AUTOSAR XML (schema 00050)
package /ComponentTypes
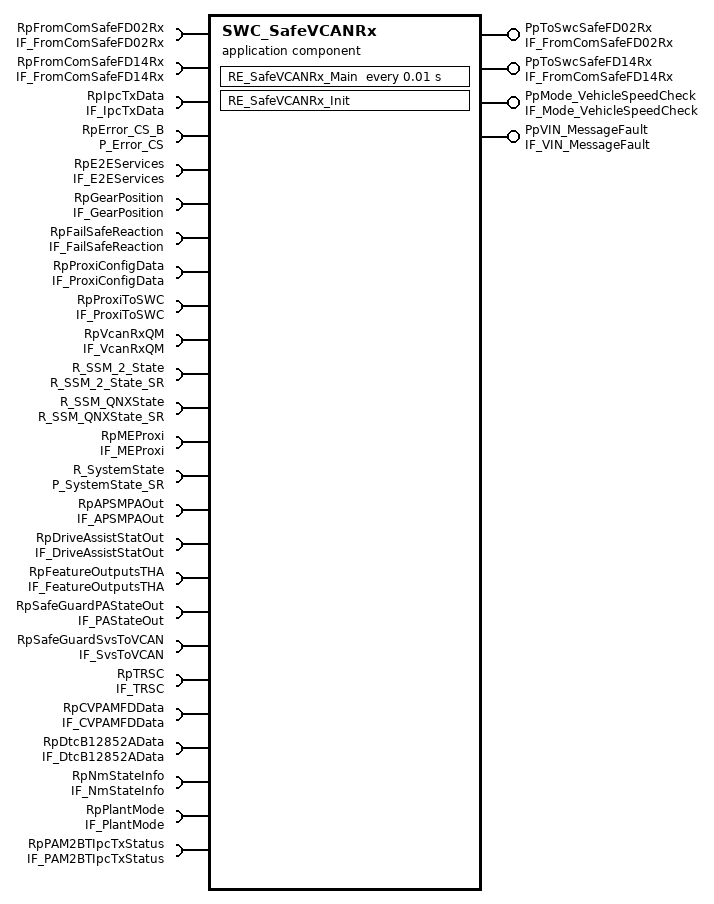
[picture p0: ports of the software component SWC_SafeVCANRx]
  application sw component type SWC_SafeVCANRx
    require port RpFromComSafeFD02Rx: required-interface=IF_FromComSafeFD02Rx
      required-com-specs:
        data-element=PdlPosActual, init-value=1
        data-element=Active_Park_Mode, enable-update=true, init-value=0
        data-element=Active_Park_Prox_Chime, enable-update=true, init-value=0
        data-element=APARequestSts, enable-update=true, init-value=0
        data-element=Backup_Cam_Delay, enable-update=true, init-value=0
        data-element=Brk_Stat, init-value=0
        data-element=CmdIgnSts, enable-update=true, init-value=0
        data-element=DriverDoorSts, enable-update=true, init-value=0
        data-element=DynamicGrid, init-value=1
        data-element=ExternalTemperature, init-value=0
        data-element=FT_PAMRequestSts, enable-update=true, init-value=0
        data-element=Fwrd_Cam_Guidelines, enable-update=true, init-value=0
        data-element=GearEngaged, enable-update=true, init-value=0
        data-element=HAS_Status_C2, init-value=0
        data-element=LanguageSelection, enable-update=true, init-value=0
        data-element=LatAcceleration_BSM, init-value=4095
        data-element=LHRDoorSts, enable-update=true, init-value=0
        data-element=LongAcceleration_BSM, init-value=4095
        data-element=LwsAngle, init-value=0
        data-element=LwsAngleType, init-value=0
        data-element=LwsSpeed, init-value=0
        data-element=MRM_STATUS_C2, init-value=0
        data-element=PamChimeVolumeFront, enable-update=true, init-value=1
        data-element=PamChimeVolumeRear, enable-update=true, init-value=1
        data-element=PAMRequestSts, enable-update=true, init-value=0
        data-element=PsngrDoorSts, enable-update=true, init-value=0
        data-element=Rear_Brk_Asst, enable-update=true, init-value=0
        data-element=RHatchSts, enable-update=true, init-value=0
        data-element=RHRDoorSts, enable-update=true, init-value=0
        data-element=ShiftLeverPosition, enable-update=true, init-value=0
        data-element=SVC_Guidelines, enable-update=true, init-value=0
        data-element=TargetGear, init-value=15
        data-element=TCASERANGESTATUS, enable-update=true, init-value=0
        data-element=TGW_CAMERA_DISP_STAT, enable-update=true, init-value=0
        data-element=TrailerConnectionSts, init-value=0
        data-element=TRANS_ADAS_Inhibit, init-value=0
        data-element=TransmissionSailingSts, init-value=0
        data-element=VehicleSpeedVSOSig, init-value=0
        data-element=YawRate_BSM, init-value=4095
        data-element=VIN_MSG, filter=data-filter-type=ALWAYS, init-value=0
        {data-element=VIN_DATA, filter=data-filter-type=ALWAYS, init-value=[rule-based-values={rule=FILL_UNTIL_END, rule-arguments=0}]}
        data-element=RR_Lvl_Adj, filter=data-filter-type=ALWAYS, init-value=0
        data-element=RR_Lvl, filter=data-filter-type=ALWAYS, init-value=254
        data-element=RL_Lvl_Adj, filter=data-filter-type=ALWAYS, init-value=0
        data-element=RL_Lvl, filter=data-filter-type=ALWAYS, init-value=254
        data-element=HU_TRSC_EnableBtn_Sts, enable-update=true, filter=data-filter-type=ALWAYS, init-value=0
        data-element=GearEngagedForDisplay, filter=data-filter-type=ALWAYS, init-value=31
        data-element=FR_Lvl_Adj, filter=data-filter-type=ALWAYS, init-value=0
        data-element=FR_Lvl, filter=data-filter-type=ALWAYS, init-value=254
        data-element=FL_Lvl_Adj, filter=data-filter-type=ALWAYS, init-value=0
        data-element=FL_Lvl, filter=data-filter-type=ALWAYS, init-value=254
        data-element=ESS_ENG_ST_W, filter=data-filter-type=ALWAYS, init-value=15
        data-element=EngineSts_W, filter=data-filter-type=ALWAYS, init-value=0
        data-element=ECM_TRSC_Resp, enable-update=true, filter=data-filter-type=ALWAYS, init-value=0
        data-element=ECM_THA_Resp, enable-update=true, filter=data-filter-type=ALWAYS, init-value=0
        data-element=ASCM_SysFail, enable-update=true, filter=data-filter-type=ALWAYS, init-value=0
        data-element=ASCM_Stat, enable-update=true, filter=data-filter-type=ALWAYS, init-value=0
        data-element=THA_SteeringTouchStat, filter=data-filter-type=ALWAYS, init-value=0
        data-element=EPS_THA_SteeringTorqueResp, filter=data-filter-type=ALWAYS, init-value=0
        data-element=EPS_THA_DriverTorqueOverride, filter=data-filter-type=ALWAYS, init-value=0
        data-element=EPS_SteeringTouq_Resp, filter=data-filter-type=ALWAYS, init-value=0
        data-element=EPS_SteeringTouchStat, filter=data-filter-type=ALWAYS, init-value=0
        data-element=ShiftLeverPositionReq, enable-update=true, filter=data-filter-type=ALWAYS, init-value=0
        data-element=Shifter_ADAS_Inhibit, filter=data-filter-type=ALWAYS, init-value=0
        data-element=ITBM_TrlrStat, enable-update=true, filter=data-filter-type=ALWAYS, init-value=0
        data-element=CM_TCH_Y_COORD, enable-update=true, filter=data-filter-type=ALWAYS, init-value=0
        data-element=CM_TCH_X_COORD, enable-update=true, filter=data-filter-type=ALWAYS, init-value=0
        data-element=CM_TCH_STAT, enable-update=true, filter=data-filter-type=ALWAYS, init-value=0
        data-element=CameraDisplaySts2, enable-update=true, filter=data-filter-type=ALWAYS, init-value=0
    require port RpFromComSafeFD14Rx: required-interface=IF_FromComSafeFD14Rx
      required-com-specs:
        data-element=FD14_PdlPosActual, init-value=1
        data-element=FD14_ACC_Systemsts, init-value=0
        data-element=FD14_Brk_Stat, init-value=0
        data-element=FD14_BrkPdl_Stat, init-value=3
        data-element=FD14_BrkTrq, init-value=32767
        data-element=FD14_BrkTrq_Driver, init-value=32767
        data-element=FD14_BSM_THA_Brk_Resp, enable-update=true, init-value=0
        data-element=FD14_EPBSts, enable-update=true, init-value=0
        data-element=FD14_EPS_HandsOnRecognition, init-value=0
        data-element=FD14_ESC_TRSC_Brk_Resp, enable-update=true, init-value=0
        data-element=FD14_ExternalBrkRequestsDisabled, init-value=0
        data-element=FD14_HAS_Status, init-value=0
        data-element=FD14_LatAcceleration_BSM, init-value=4095
        data-element=FD14_LatAccelerationFailSts_BSM, init-value=0
        data-element=FD14_LatAccelerationOffset_BSM, init-value=255
        data-element=FD14_LHF_FastPulseCounter, init-value=0
        data-element=FD14_LHF_Spin, init-value=0
        data-element=FD14_LHF_WheelSensorFailSts, init-value=0
        data-element=FD14_LHFWheelSpeed, init-value=0
        data-element=FD14_LHR_FastPulseCounter, init-value=0
        data-element=FD14_LHR_Spin, init-value=0
        data-element=FD14_LHR_WheelSensorFailSts, init-value=0
        data-element=FD14_LHRWheelSpeed, init-value=0
        data-element=FD14_LongAcceleration_BSM, init-value=4095
        data-element=FD14_LongAccelerationFailSts_BSM, init-value=0
        data-element=FD14_LongAccelerationOffset_BSM, init-value=255
        data-element=FD14_LwsAngle, init-value=0
        data-element=FD14_LwsAngleType, init-value=0
        data-element=FD14_LwsSpeed, init-value=0
        data-element=FD14_PAM_Brk_Rq_RspSts, init-value=0
        data-element=FD14_ParkingGearShiftReq_BSM, init-value=0
        data-element=FD14_ParkingInterventionSts, init-value=0
        data-element=FD14_REF_VEH_SPEED, init-value=1023
        data-element=FD14_RHF_FastPulseCounter, init-value=0
        data-element=FD14_RHF_Spin, init-value=0
        data-element=FD14_RHF_WheelSensorFailSts, init-value=0
        data-element=FD14_RHFWheelSpeed, init-value=0
        data-element=FD14_RHR_FastPulseCounter, init-value=0
        data-element=FD14_RHR_Spin, init-value=0
        data-element=FD14_RHR_WheelSensorFailSts, init-value=0
        data-element=FD14_RHRWheelSpeed, init-value=0
        data-element=FD14_Slope, init-value=0
        data-element=FD14_SPM_Lat_Ctrl_ResponseSts, init-value=0
        data-element=FD14_Steering_Column_Torque, init-value=0
        data-element=FD14_VehicleSpeedVSOSig, init-value=0
        data-element=FD14_VehicleSpeedVSOSig_B2, init-value=0
        data-element=FD14_VehicleStandStillSts, init-value=1
        data-element=FD14_YawRate_BSM, init-value=4095
        data-element=FD14_YawRateFailSts_BSM, init-value=0
        data-element=FD14_ESS_ENG_ST_W, enable-update=true, filter=data-filter-type=ALWAYS, init-value=15
        data-element=FD14_EngineSts_W, filter=data-filter-type=ALWAYS, init-value=3
        data-element=FD14_ECM_TRSC_Resp, enable-update=true, filter=data-filter-type=ALWAYS, init-value=0
        data-element=FD14_ECM_THA_Resp, enable-update=true, filter=data-filter-type=ALWAYS, init-value=0
        data-element=FD14_THA_SteeringTouchStat, filter=data-filter-type=ALWAYS, init-value=0
        data-element=FD14_EPS_THA_SteeringTorqueResp, filter=data-filter-type=ALWAYS, init-value=0
        data-element=FD14_EPS_THA_DriverTorqueOverride, filter=data-filter-type=ALWAYS, init-value=0
        data-element=FD14_EPS_SteeringTouq_Resp, filter=data-filter-type=ALWAYS, init-value=0
        data-element=FD14_EPS_SteeringTouchStat, filter=data-filter-type=ALWAYS, init-value=0
    provide port PpToSwcSafeFD02Rx: provided-interface=IF_FromComSafeFD02Rx
      provided-com-specs:
        data-element=CameraDisplaySts2, init-value=0
        data-element=CM_TCH_STAT, init-value=0
        data-element=CM_TCH_X_COORD, init-value=0
        data-element=CM_TCH_Y_COORD, init-value=0
        data-element=EPS_SteeringTouchStat, init-value=0
        data-element=EPS_SteeringTouq_Resp, init-value=0
        data-element=EPS_THA_DriverTorqueOverride, init-value=0
        data-element=EPS_THA_SteeringTorqueResp, init-value=0
        data-element=THA_SteeringTouchStat, init-value=0
        data-element=ITBM_TrlrStat, init-value=0
        data-element=Shifter_ADAS_Inhibit, init-value=0
        data-element=ShiftLeverPositionReq, init-value=0
        data-element=PdlPosActual, init-value=1
        data-element=ASCM_Stat, init-value=0
        data-element=ASCM_SysFail, init-value=0
        data-element=ECM_THA_Resp, init-value=0
        data-element=ECM_TRSC_Resp, init-value=0
        data-element=EngineSts_W, init-value=3
        data-element=ESS_ENG_ST_W, init-value=15
        data-element=FL_Lvl, init-value=254
        data-element=FL_Lvl_Adj, init-value=0
        data-element=FR_Lvl, init-value=254
        data-element=FR_Lvl_Adj, init-value=0
        data-element=GearEngagedForDisplay, init-value=31
        data-element=HU_TRSC_EnableBtn_Sts, init-value=0
        data-element=RL_Lvl, init-value=254
        data-element=RL_Lvl_Adj, init-value=0
        data-element=RR_Lvl, init-value=254
        data-element=RR_Lvl_Adj, init-value=0
        {data-element=VIN_DATA, init-value=[rule-based-values={rule=FILL_UNTIL_END, rule-arguments=0}]}
        data-element=VIN_MSG, init-value=3
        data-element=Active_Park_Mode, init-value=0
        data-element=Active_Park_Prox_Chime, init-value=0
        data-element=APARequestSts, init-value=0
        data-element=Backup_Cam_Delay, init-value=0
        data-element=Brk_Stat, init-value=0
        data-element=CmdIgnSts, init-value=0
        data-element=DriverDoorSts, init-value=0
        data-element=DynamicGrid, init-value=1
        data-element=ExternalTemperature, init-value=0
        data-element=FT_PAMRequestSts, init-value=0
        data-element=Fwrd_Cam_Guidelines, init-value=0
        data-element=GearEngaged, init-value=0
        data-element=HAS_Status_C2, init-value=0
        data-element=LanguageSelection, init-value=0
        data-element=LatAcceleration_BSM, init-value=4095
        data-element=LHRDoorSts, init-value=0
        data-element=LongAcceleration_BSM, init-value=4095
        data-element=LwsAngle, init-value=0
        data-element=LwsAngleType, init-value=0
        data-element=LwsSpeed, init-value=0
        data-element=MRM_STATUS_C2, init-value=0
        data-element=PamChimeVolumeFront, init-value=1
        data-element=PamChimeVolumeRear, init-value=1
        data-element=PAMRequestSts, init-value=0
        data-element=PsngrDoorSts, init-value=0
        data-element=Rear_Brk_Asst, init-value=0
        data-element=RHatchSts, init-value=0
        data-element=RHRDoorSts, init-value=0
        data-element=ShiftLeverPosition, init-value=0
        data-element=SVC_Guidelines, init-value=0
        data-element=TargetGear, init-value=15
        data-element=TCASERANGESTATUS, init-value=0
        data-element=TGW_CAMERA_DISP_STAT, init-value=0
        data-element=TrailerConnectionSts, init-value=0
        data-element=TRANS_ADAS_Inhibit, init-value=0
        data-element=TransmissionSailingSts, init-value=0
        data-element=VehicleSpeedVSOSig, init-value=0
        data-element=YawRate_BSM, init-value=4095
    provide port PpToSwcSafeFD14Rx: provided-interface=IF_FromComSafeFD14Rx
      provided-com-specs:
        data-element=FD14_EPS_SteeringTouchStat, init-value=0
        data-element=FD14_EPS_SteeringTouq_Resp, init-value=0
        data-element=FD14_EPS_THA_DriverTorqueOverride, init-value=0
        data-element=FD14_EPS_THA_SteeringTorqueResp, init-value=0
        data-element=FD14_THA_SteeringTouchStat, init-value=0
        data-element=FD14_PdlPosActual, init-value=1
        data-element=FD14_ECM_THA_Resp, init-value=0
        data-element=FD14_ECM_TRSC_Resp, init-value=0
        data-element=FD14_EngineSts_W, init-value=3
        data-element=FD14_ESS_ENG_ST_W, init-value=15
        data-element=FD14_ACC_Systemsts, init-value=0
        data-element=FD14_Brk_Stat, init-value=0
        data-element=FD14_BrkPdl_Stat, init-value=3
        data-element=FD14_BrkTrq, init-value=32767
        data-element=FD14_BrkTrq_Driver, init-value=32767
        data-element=FD14_BSM_THA_Brk_Resp, init-value=0
        data-element=FD14_EPBSts, init-value=0
        data-element=FD14_EPS_HandsOnRecognition, init-value=0
        data-element=FD14_ESC_TRSC_Brk_Resp, init-value=0
        data-element=FD14_ExternalBrkRequestsDisabled, init-value=0
        data-element=FD14_HAS_Status, init-value=0
        data-element=FD14_LatAcceleration_BSM, init-value=4095
        data-element=FD14_LatAccelerationFailSts_BSM, init-value=0
        data-element=FD14_LatAccelerationOffset_BSM, init-value=255
        data-element=FD14_LHF_FastPulseCounter, init-value=0
        data-element=FD14_LHF_Spin, init-value=0
        data-element=FD14_LHF_WheelSensorFailSts, init-value=0
        data-element=FD14_LHFWheelSpeed, init-value=0
        data-element=FD14_LHR_FastPulseCounter, init-value=0
        data-element=FD14_LHR_Spin, init-value=0
        data-element=FD14_LHR_WheelSensorFailSts, init-value=0
        data-element=FD14_LHRWheelSpeed, init-value=0
        data-element=FD14_LongAcceleration_BSM, init-value=4095
        data-element=FD14_LongAccelerationFailSts_BSM, init-value=0
        data-element=FD14_LongAccelerationOffset_BSM, init-value=255
        data-element=FD14_LwsAngle, init-value=0
        data-element=FD14_LwsAngleType, init-value=0
        data-element=FD14_LwsSpeed, init-value=0
        data-element=FD14_PAM_Brk_Rq_RspSts, init-value=0
        data-element=FD14_ParkingGearShiftReq_BSM, init-value=0
        data-element=FD14_ParkingInterventionSts, init-value=0
        data-element=FD14_REF_VEH_SPEED, init-value=1023
        data-element=FD14_RHF_FastPulseCounter, init-value=0
        data-element=FD14_RHF_Spin, init-value=0
        data-element=FD14_RHF_WheelSensorFailSts, init-value=0
        data-element=FD14_RHFWheelSpeed, init-value=0
        data-element=FD14_RHR_FastPulseCounter, init-value=0
        data-element=FD14_RHR_Spin, init-value=0
        data-element=FD14_RHR_WheelSensorFailSts, init-value=0
        data-element=FD14_RHRWheelSpeed, init-value=0
        data-element=FD14_Slope, init-value=0
        data-element=FD14_SPM_Lat_Ctrl_ResponseSts, init-value=0
        data-element=FD14_Steering_Column_Torque, init-value=0
        data-element=FD14_VehicleSpeedVSOSig, init-value=0
        data-element=FD14_VehicleSpeedVSOSig_B2, init-value=0
        data-element=FD14_VehicleStandStillSts, init-value=1
        data-element=FD14_YawRate_BSM, init-value=4095
        data-element=FD14_YawRateFailSts_BSM, init-value=0
    require port RpIpcTxData: client-com-spec=IPC_Write_v, required-interface=IF_IpcTxData
    provide port PpMode_VehicleSpeedCheck: mode-switch-sender-com-spec{mode-group=Mode, queue-length=1}, provided-interface=IF_Mode_VehicleSpeedCheck
    21 x require port:
      RpError_CS_B: client-com-spec=ReportErrorStatus1_0_B, required-interface=P_Error_CS
      RpE2EServices: required-com-specs=[ME_E2E_Check, ME_E2E_Protect], required-interface=IF_E2EServices
      RpGearPosition: required-interface=IF_GearPosition
        required-com-specs:
          data-element=GearValue, filter=data-filter-type=ALWAYS, init-value=0
          data-element=ShortTermAdjActiveFlag_b, filter=data-filter-type=ALWAYS, init-value=0
      RpFailSafeReaction: nonqueued-receiver-com-spec{data-element=State, filter=data-filter-type=ALWAYS, init-value=0}, required-interface=IF_FailSafeReaction
      RpProxiConfigData: nonqueued-receiver-com-spec{data-element=ProxiData, filter=data-filter-type=ALWAYS}, required-interface=IF_ProxiConfigData
      RpProxiToSWC: required-interface=IF_ProxiToSWC
        required-com-specs:
          data-element=TyreSz_u16, filter=data-filter-type=ALWAYS
          data-element=SurroundViewCam_u8, filter=data-filter-type=ALWAYS
          data-element=Fullautomaticparking, filter=data-filter-type=ALWAYS
          data-element=Pamtuningset, filter=data-filter-type=ALWAYS
          data-element=Parkwithstop_u8, filter=data-filter-type=ALWAYS
          data-element=Trailerhitchassist_u8, filter=data-filter-type=ALWAYS
          data-element=PAMConfig_u8, filter=data-filter-type=ALWAYS
          data-element=PRX_CanNod27_b, filter=data-filter-type=ALWAYS
      RpVcanRxQM: nonqueued-receiver-com-spec{data-element=ME_VehInp_to_IpcSignals_QM_t, filter=data-filter-type=ALWAYS}, required-interface=IF_VcanRxQM
      R_SSM_2_State: required-interface=R_SSM_2_State_SR
        required-com-specs:
          data-element=State_2_0, init-value=fields=[CoreStatus:0, LocalAppStatus:20 x 0]
          data-element=State_2_1, filter=data-filter-type=ALWAYS, init-value=fields=[CoreStatus:0, LocalAppStatus:20 x 0]
      R_SSM_QNXState: nonqueued-receiver-com-spec{data-element=State_QNX, init-value=fields=[CoreStatus:0, LocalAppStatus:20 x 0]}, required-interface=R_SSM_QNXState_SR
      RpMEProxi: nonqueued-receiver-com-spec{data-element=ME_Proxi_MPU1_0_to_MCU1_0_t, filter=data-filter-type=ALWAYS}, required-interface=IF_MEProxi
      R_SystemState: nonqueued-receiver-com-spec=data-element=SystemState, required-interface=P_SystemState_SR
      RpAPSMPAOut: nonqueued-receiver-com-spec=data-element=TbAP_APSMPAOut_t, required-interface=IF_APSMPAOut
      RpDriveAssistStatOut: nonqueued-receiver-com-spec=data-element=TbAP_DriveAssistStatOut_t, required-interface=IF_DriveAssistStatOut
      RpFeatureOutputsTHA: nonqueued-receiver-com-spec=data-element=TbTHASmVc_FeatureOutputs_t, required-interface=IF_FeatureOutputsTHA
      RpSafeGuardPAStateOut: nonqueued-receiver-com-spec=data-element=TbAP_PAStateOut_t, required-interface=IF_PAStateOut
      RpSafeGuardSvsToVCAN: nonqueued-receiver-com-spec=data-element=SvsToVCAN_t, required-interface=IF_SvsToVCAN
      RpTRSC: nonqueued-receiver-com-spec=data-element=ME_VehOut_TRSC_t, required-interface=IF_TRSC
      RpCVPAMFDData: nonqueued-receiver-com-spec=data-element=IFOD_Outputs_CVPAMFDData_t, required-interface=IF_CVPAMFDData
      RpDtcB12852AData: nonqueued-receiver-com-spec{data-element=v_DtcData_u8, filter=data-filter-type=ALWAYS, init-value=0}, required-interface=IF_DtcB12852AData
      RpNmStateInfo: nonqueued-receiver-com-spec{data-element=v_IsNmStateNormal_b, filter=data-filter-type=ALWAYS, init-value=0}, required-interface=IF_NmStateInfo
      RpPlantMode: nonqueued-receiver-com-spec{data-element=Status, filter=data-filter-type=ALWAYS, init-value=0}, required-interface=IF_PlantMode
    provide port PpVIN_MessageFault: provided-com-specs=[{data-element=VIN_InvalidValueFlag, init-value=0}, {data-element=VIN_MissingMessageFlag, init-value=0}], provided-interface=IF_VIN_MessageFault
    require port RpPAM2BTIpcTxStatus: nonqueued-receiver-com-spec{data-element=IpcTxDone, filter=data-filter-type=ALWAYS}, required-interface=IF_PAM2BTIpcTxStatus
    behavior SWC_SafeVCANRx_InternalBehavior: data-type-mapping=defaultDataTypeMappingSet_CPFS
      init event SWC_SafeVCANRx_InitEvent: start-on-event=RE_SafeVCANRx_Init
      timing event TMT_RE_SafeVCANRx_Main: start-on-event=RE_SafeVCANRx_Main, period=0.01
      runnable RE_SafeVCANRx_Init
      runnable RE_SafeVCANRx_Main
        data-receive-point-by-arguments:
          154 x access:
            REC_RpFromComSafeFD02Rx_APARequestSts: accessed-variable=RpFromComSafeFD02Rx.APARequestSts
            REC_RpFromComSafeFD02Rx_Active_Park_Mode: accessed-variable=RpFromComSafeFD02Rx.Active_Park_Mode
            REC_RpFromComSafeFD02Rx_Active_Park_Prox_Chime: accessed-variable=RpFromComSafeFD02Rx.Active_Park_Prox_Chime
            REC_RpFromComSafeFD02Rx_Backup_Cam_Delay: accessed-variable=RpFromComSafeFD02Rx.Backup_Cam_Delay
            REC_RpFromComSafeFD02Rx_Brk_Stat: accessed-variable=RpFromComSafeFD02Rx.Brk_Stat
            REC_RpFromComSafeFD02Rx_CmdIgnSts: accessed-variable=RpFromComSafeFD02Rx.CmdIgnSts
            REC_RpFromComSafeFD02Rx_DriverDoorSts: accessed-variable=RpFromComSafeFD02Rx.DriverDoorSts
            REC_RpFromComSafeFD02Rx_DynamicGrid: accessed-variable=RpFromComSafeFD02Rx.DynamicGrid
            REC_RpFromComSafeFD02Rx_ExternalTemperature: accessed-variable=RpFromComSafeFD02Rx.ExternalTemperature
            REC_RpFromComSafeFD02Rx_FT_PAMRequestSts: accessed-variable=RpFromComSafeFD02Rx.FT_PAMRequestSts
            REC_RpFromComSafeFD02Rx_Fwrd_Cam_Guidelines: accessed-variable=RpFromComSafeFD02Rx.Fwrd_Cam_Guidelines
            REC_RpFromComSafeFD02Rx_GearEngaged: accessed-variable=RpFromComSafeFD02Rx.GearEngaged
            REC_RpFromComSafeFD02Rx_HAS_Status_C2: accessed-variable=RpFromComSafeFD02Rx.HAS_Status_C2
            REC_RpFromComSafeFD02Rx_LHRDoorSts: accessed-variable=RpFromComSafeFD02Rx.LHRDoorSts
            REC_RpFromComSafeFD02Rx_LanguageSelection: accessed-variable=RpFromComSafeFD02Rx.LanguageSelection
            REC_RpFromComSafeFD02Rx_LatAcceleration_BSM: accessed-variable=RpFromComSafeFD02Rx.LatAcceleration_BSM
            REC_RpFromComSafeFD02Rx_LongAcceleration_BSM: accessed-variable=RpFromComSafeFD02Rx.LongAcceleration_BSM
            REC_RpFromComSafeFD02Rx_LwsAngle: accessed-variable=RpFromComSafeFD02Rx.LwsAngle
            REC_RpFromComSafeFD02Rx_LwsAngleType: accessed-variable=RpFromComSafeFD02Rx.LwsAngleType
            REC_RpFromComSafeFD02Rx_LwsSpeed: accessed-variable=RpFromComSafeFD02Rx.LwsSpeed
            REC_RpFromComSafeFD02Rx_MRM_STATUS_C2: accessed-variable=RpFromComSafeFD02Rx.MRM_STATUS_C2
            REC_RpFromComSafeFD02Rx_PAMRequestSts: accessed-variable=RpFromComSafeFD02Rx.PAMRequestSts
            REC_RpFromComSafeFD02Rx_PamChimeVolumeFront: accessed-variable=RpFromComSafeFD02Rx.PamChimeVolumeFront
            REC_RpFromComSafeFD02Rx_PamChimeVolumeRear: accessed-variable=RpFromComSafeFD02Rx.PamChimeVolumeRear
            REC_RpFromComSafeFD02Rx_PsngrDoorSts: accessed-variable=RpFromComSafeFD02Rx.PsngrDoorSts
            REC_RpFromComSafeFD02Rx_RHRDoorSts: accessed-variable=RpFromComSafeFD02Rx.RHRDoorSts
            REC_RpFromComSafeFD02Rx_RHatchSts: accessed-variable=RpFromComSafeFD02Rx.RHatchSts
            REC_RpFromComSafeFD02Rx_Rear_Brk_Asst: accessed-variable=RpFromComSafeFD02Rx.Rear_Brk_Asst
            REC_RpFromComSafeFD02Rx_SVC_Guidelines: accessed-variable=RpFromComSafeFD02Rx.SVC_Guidelines
            REC_RpFromComSafeFD02Rx_ShiftLeverPosition: accessed-variable=RpFromComSafeFD02Rx.ShiftLeverPosition
            REC_RpFromComSafeFD02Rx_TCASERANGESTATUS: accessed-variable=RpFromComSafeFD02Rx.TCASERANGESTATUS
            REC_RpFromComSafeFD02Rx_TGW_CAMERA_DISP_STAT: accessed-variable=RpFromComSafeFD02Rx.TGW_CAMERA_DISP_STAT
            REC_RpFromComSafeFD02Rx_TRANS_ADAS_Inhibit: accessed-variable=RpFromComSafeFD02Rx.TRANS_ADAS_Inhibit
            REC_RpFromComSafeFD02Rx_TargetGear: accessed-variable=RpFromComSafeFD02Rx.TargetGear
            REC_RpFromComSafeFD02Rx_TrailerConnectionSts: accessed-variable=RpFromComSafeFD02Rx.TrailerConnectionSts
            REC_RpFromComSafeFD02Rx_TransmissionSailingSts: accessed-variable=RpFromComSafeFD02Rx.TransmissionSailingSts
            REC_RpFromComSafeFD02Rx_VehicleSpeedVSOSig: accessed-variable=RpFromComSafeFD02Rx.VehicleSpeedVSOSig
            REC_RpFromComSafeFD02Rx_YawRate_BSM: accessed-variable=RpFromComSafeFD02Rx.YawRate_BSM
            REC_RpFromComSafeFD14Rx_FD14_ACC_Systemsts: accessed-variable=RpFromComSafeFD14Rx.FD14_ACC_Systemsts
            REC_RpFromComSafeFD14Rx_FD14_BSM_THA_Brk_Resp: accessed-variable=RpFromComSafeFD14Rx.FD14_BSM_THA_Brk_Resp
            REC_RpFromComSafeFD14Rx_FD14_BrkPdl_Stat: accessed-variable=RpFromComSafeFD14Rx.FD14_BrkPdl_Stat
            REC_RpFromComSafeFD14Rx_FD14_BrkTrq: accessed-variable=RpFromComSafeFD14Rx.FD14_BrkTrq
            REC_RpFromComSafeFD14Rx_FD14_BrkTrq_Driver: accessed-variable=RpFromComSafeFD14Rx.FD14_BrkTrq_Driver
            REC_RpFromComSafeFD14Rx_FD14_Brk_Stat: accessed-variable=RpFromComSafeFD14Rx.FD14_Brk_Stat
            REC_RpFromComSafeFD14Rx_FD14_EPBSts: accessed-variable=RpFromComSafeFD14Rx.FD14_EPBSts
            REC_RpFromComSafeFD14Rx_FD14_EPS_HandsOnRecognition: accessed-variable=RpFromComSafeFD14Rx.FD14_EPS_HandsOnRecognition
            REC_RpFromComSafeFD14Rx_FD14_ESC_TRSC_Brk_Resp: accessed-variable=RpFromComSafeFD14Rx.FD14_ESC_TRSC_Brk_Resp
            REC_RpFromComSafeFD14Rx_FD14_ExternalBrkRequestsDisabled: accessed-variable=RpFromComSafeFD14Rx.FD14_ExternalBrkRequestsDisabled
            REC_RpFromComSafeFD14Rx_FD14_HAS_Status: accessed-variable=RpFromComSafeFD14Rx.FD14_HAS_Status
            REC_RpFromComSafeFD14Rx_FD14_LHFWheelSpeed: accessed-variable=RpFromComSafeFD14Rx.FD14_LHFWheelSpeed
            REC_RpFromComSafeFD14Rx_FD14_LHF_FastPulseCounter: accessed-variable=RpFromComSafeFD14Rx.FD14_LHF_FastPulseCounter
            REC_RpFromComSafeFD14Rx_FD14_LHF_Spin: accessed-variable=RpFromComSafeFD14Rx.FD14_LHF_Spin
            REC_RpFromComSafeFD14Rx_FD14_LHF_WheelSensorFailSts: accessed-variable=RpFromComSafeFD14Rx.FD14_LHF_WheelSensorFailSts
            REC_RpFromComSafeFD14Rx_FD14_LHRWheelSpeed: accessed-variable=RpFromComSafeFD14Rx.FD14_LHRWheelSpeed
            REC_RpFromComSafeFD14Rx_FD14_LHR_FastPulseCounter: accessed-variable=RpFromComSafeFD14Rx.FD14_LHR_FastPulseCounter
            REC_RpFromComSafeFD14Rx_FD14_LHR_Spin: accessed-variable=RpFromComSafeFD14Rx.FD14_LHR_Spin
            REC_RpFromComSafeFD14Rx_FD14_LHR_WheelSensorFailSts: accessed-variable=RpFromComSafeFD14Rx.FD14_LHR_WheelSensorFailSts
            REC_RpFromComSafeFD14Rx_FD14_LatAccelerationFailSts_BSM: accessed-variable=RpFromComSafeFD14Rx.FD14_LatAccelerationFailSts_BSM
            REC_RpFromComSafeFD14Rx_FD14_LatAccelerationOffset_BSM: accessed-variable=RpFromComSafeFD14Rx.FD14_LatAccelerationOffset_BSM
            REC_RpFromComSafeFD14Rx_FD14_LatAcceleration_BSM: accessed-variable=RpFromComSafeFD14Rx.FD14_LatAcceleration_BSM
            REC_RpFromComSafeFD14Rx_FD14_LongAccelerationFailSts_BSM: accessed-variable=RpFromComSafeFD14Rx.FD14_LongAccelerationFailSts_BSM
            REC_RpFromComSafeFD14Rx_FD14_LongAccelerationOffset_BSM: accessed-variable=RpFromComSafeFD14Rx.FD14_LongAccelerationOffset_BSM
            REC_RpFromComSafeFD14Rx_FD14_LongAcceleration_BSM: accessed-variable=RpFromComSafeFD14Rx.FD14_LongAcceleration_BSM
            REC_RpFromComSafeFD14Rx_FD14_LwsAngle: accessed-variable=RpFromComSafeFD14Rx.FD14_LwsAngle
            REC_RpFromComSafeFD14Rx_FD14_LwsAngleType: accessed-variable=RpFromComSafeFD14Rx.FD14_LwsAngleType
            REC_RpFromComSafeFD14Rx_FD14_LwsSpeed: accessed-variable=RpFromComSafeFD14Rx.FD14_LwsSpeed
            REC_RpFromComSafeFD14Rx_FD14_PAM_Brk_Rq_RspSts: accessed-variable=RpFromComSafeFD14Rx.FD14_PAM_Brk_Rq_RspSts
            REC_RpFromComSafeFD14Rx_FD14_ParkingGearShiftReq_BSM: accessed-variable=RpFromComSafeFD14Rx.FD14_ParkingGearShiftReq_BSM
            REC_RpFromComSafeFD14Rx_FD14_ParkingInterventionSts: accessed-variable=RpFromComSafeFD14Rx.FD14_ParkingInterventionSts
            REC_RpFromComSafeFD14Rx_FD14_REF_VEH_SPEED: accessed-variable=RpFromComSafeFD14Rx.FD14_REF_VEH_SPEED
            REC_RpFromComSafeFD14Rx_FD14_RHFWheelSpeed: accessed-variable=RpFromComSafeFD14Rx.FD14_RHFWheelSpeed
            REC_RpFromComSafeFD14Rx_FD14_RHF_FastPulseCounter: accessed-variable=RpFromComSafeFD14Rx.FD14_RHF_FastPulseCounter
            REC_RpFromComSafeFD14Rx_FD14_RHF_Spin: accessed-variable=RpFromComSafeFD14Rx.FD14_RHF_Spin
            REC_RpFromComSafeFD14Rx_FD14_RHF_WheelSensorFailSts: accessed-variable=RpFromComSafeFD14Rx.FD14_RHF_WheelSensorFailSts
            REC_RpFromComSafeFD14Rx_FD14_RHRWheelSpeed: accessed-variable=RpFromComSafeFD14Rx.FD14_RHRWheelSpeed
            REC_RpFromComSafeFD14Rx_FD14_RHR_FastPulseCounter: accessed-variable=RpFromComSafeFD14Rx.FD14_RHR_FastPulseCounter
            REC_RpFromComSafeFD14Rx_FD14_RHR_Spin: accessed-variable=RpFromComSafeFD14Rx.FD14_RHR_Spin
            REC_RpFromComSafeFD14Rx_FD14_RHR_WheelSensorFailSts: accessed-variable=RpFromComSafeFD14Rx.FD14_RHR_WheelSensorFailSts
            REC_RpFromComSafeFD14Rx_FD14_SPM_Lat_Ctrl_ResponseSts: accessed-variable=RpFromComSafeFD14Rx.FD14_SPM_Lat_Ctrl_ResponseSts
            REC_RpFromComSafeFD14Rx_FD14_Slope: accessed-variable=RpFromComSafeFD14Rx.FD14_Slope
            REC_RpFromComSafeFD14Rx_FD14_Steering_Column_Torque: accessed-variable=RpFromComSafeFD14Rx.FD14_Steering_Column_Torque
            REC_RpFromComSafeFD14Rx_FD14_VehicleSpeedVSOSig: accessed-variable=RpFromComSafeFD14Rx.FD14_VehicleSpeedVSOSig
            REC_RpFromComSafeFD14Rx_FD14_VehicleSpeedVSOSig_B2: accessed-variable=RpFromComSafeFD14Rx.FD14_VehicleSpeedVSOSig_B2
            REC_RpFromComSafeFD14Rx_FD14_VehicleStandStillSts: accessed-variable=RpFromComSafeFD14Rx.FD14_VehicleStandStillSts
            REC_RpFromComSafeFD14Rx_FD14_YawRateFailSts_BSM: accessed-variable=RpFromComSafeFD14Rx.FD14_YawRateFailSts_BSM
            REC_RpFromComSafeFD14Rx_FD14_YawRate_BSM: accessed-variable=RpFromComSafeFD14Rx.FD14_YawRate_BSM
            REC_RpGearPosition_ShortTermAdjActiveFlag_b: accessed-variable=RpGearPosition.ShortTermAdjActiveFlag_b
            REC_RpGearPosition_GearValue: accessed-variable=RpGearPosition.GearValue
            REC_RpFailSafeReaction_State: accessed-variable=RpFailSafeReaction.State
            REC_RpFromComSafeFD02Rx_ASCM_Stat: accessed-variable=RpFromComSafeFD02Rx.ASCM_Stat
            REC_RpFromComSafeFD02Rx_ASCM_SysFail: accessed-variable=RpFromComSafeFD02Rx.ASCM_SysFail
            REC_RpFromComSafeFD02Rx_ECM_THA_Resp: accessed-variable=RpFromComSafeFD02Rx.ECM_THA_Resp
            REC_RpFromComSafeFD02Rx_ECM_TRSC_Resp: accessed-variable=RpFromComSafeFD02Rx.ECM_TRSC_Resp
            REC_RpFromComSafeFD02Rx_ESS_ENG_ST_W: accessed-variable=RpFromComSafeFD02Rx.ESS_ENG_ST_W
            REC_RpFromComSafeFD02Rx_EngineSts_W: accessed-variable=RpFromComSafeFD02Rx.EngineSts_W
            REC_RpFromComSafeFD02Rx_FL_Lvl: accessed-variable=RpFromComSafeFD02Rx.FL_Lvl
            REC_RpFromComSafeFD02Rx_FL_Lvl_Adj: accessed-variable=RpFromComSafeFD02Rx.FL_Lvl_Adj
            REC_RpFromComSafeFD02Rx_FR_Lvl: accessed-variable=RpFromComSafeFD02Rx.FR_Lvl
            REC_RpFromComSafeFD02Rx_FR_Lvl_Adj: accessed-variable=RpFromComSafeFD02Rx.FR_Lvl_Adj
            REC_RpFromComSafeFD02Rx_GearEngagedForDisplay: accessed-variable=RpFromComSafeFD02Rx.GearEngagedForDisplay
            REC_RpFromComSafeFD02Rx_HU_TRSC_EnableBtn_Sts: accessed-variable=RpFromComSafeFD02Rx.HU_TRSC_EnableBtn_Sts
            REC_RpFromComSafeFD02Rx_RL_Lvl: accessed-variable=RpFromComSafeFD02Rx.RL_Lvl
            REC_RpFromComSafeFD02Rx_RL_Lvl_Adj: accessed-variable=RpFromComSafeFD02Rx.RL_Lvl_Adj
            REC_RpFromComSafeFD02Rx_RR_Lvl: accessed-variable=RpFromComSafeFD02Rx.RR_Lvl
            REC_RpFromComSafeFD02Rx_RR_Lvl_Adj: accessed-variable=RpFromComSafeFD02Rx.RR_Lvl_Adj
            REC_RpFromComSafeFD02Rx_VIN_DATA: accessed-variable=RpFromComSafeFD02Rx.VIN_DATA
            REC_RpFromComSafeFD02Rx_VIN_MSG: accessed-variable=RpFromComSafeFD02Rx.VIN_MSG
            REC_RpFromComSafeFD14Rx_FD14_ECM_THA_Resp: accessed-variable=RpFromComSafeFD14Rx.FD14_ECM_THA_Resp
            REC_RpFromComSafeFD14Rx_FD14_ECM_TRSC_Resp: accessed-variable=RpFromComSafeFD14Rx.FD14_ECM_TRSC_Resp
            REC_RpFromComSafeFD14Rx_FD14_ESS_ENG_ST_W: accessed-variable=RpFromComSafeFD14Rx.FD14_ESS_ENG_ST_W
            REC_RpFromComSafeFD14Rx_FD14_EngineSts_W: accessed-variable=RpFromComSafeFD14Rx.FD14_EngineSts_W
            REC_RpFromComSafeFD02Rx_PdlPosActual: accessed-variable=RpFromComSafeFD02Rx.PdlPosActual
            REC_RpFromComSafeFD14Rx_FD14_PdlPosActual: accessed-variable=RpFromComSafeFD14Rx.FD14_PdlPosActual
            REC_RpFromComSafeFD02Rx_CM_TCH_STAT: accessed-variable=RpFromComSafeFD02Rx.CM_TCH_STAT
            REC_RpFromComSafeFD02Rx_CM_TCH_X_COORD: accessed-variable=RpFromComSafeFD02Rx.CM_TCH_X_COORD
            REC_RpFromComSafeFD02Rx_CM_TCH_Y_COORD: accessed-variable=RpFromComSafeFD02Rx.CM_TCH_Y_COORD
            REC_RpFromComSafeFD02Rx_CameraDisplaySts2: accessed-variable=RpFromComSafeFD02Rx.CameraDisplaySts2
            REC_RpFromComSafeFD02Rx_EPS_SteeringTouchStat: accessed-variable=RpFromComSafeFD02Rx.EPS_SteeringTouchStat
            REC_RpFromComSafeFD02Rx_EPS_SteeringTouq_Resp: accessed-variable=RpFromComSafeFD02Rx.EPS_SteeringTouq_Resp
            REC_RpFromComSafeFD02Rx_EPS_THA_DriverTorqueOverride: accessed-variable=RpFromComSafeFD02Rx.EPS_THA_DriverTorqueOverride
            REC_RpFromComSafeFD02Rx_EPS_THA_SteeringTorqueResp: accessed-variable=RpFromComSafeFD02Rx.EPS_THA_SteeringTorqueResp
            REC_RpFromComSafeFD02Rx_ITBM_TrlrStat: accessed-variable=RpFromComSafeFD02Rx.ITBM_TrlrStat
            REC_RpFromComSafeFD02Rx_ShiftLeverPositionReq: accessed-variable=RpFromComSafeFD02Rx.ShiftLeverPositionReq
            REC_RpFromComSafeFD02Rx_Shifter_ADAS_Inhibit: accessed-variable=RpFromComSafeFD02Rx.Shifter_ADAS_Inhibit
            REC_RpFromComSafeFD02Rx_THA_SteeringTouchStat: accessed-variable=RpFromComSafeFD02Rx.THA_SteeringTouchStat
            REC_RpFromComSafeFD14Rx_FD14_EPS_SteeringTouchStat: accessed-variable=RpFromComSafeFD14Rx.FD14_EPS_SteeringTouchStat
            REC_RpFromComSafeFD14Rx_FD14_EPS_SteeringTouq_Resp: accessed-variable=RpFromComSafeFD14Rx.FD14_EPS_SteeringTouq_Resp
            REC_RpFromComSafeFD14Rx_FD14_EPS_THA_DriverTorqueOverride: accessed-variable=RpFromComSafeFD14Rx.FD14_EPS_THA_DriverTorqueOverride
            REC_RpFromComSafeFD14Rx_FD14_EPS_THA_SteeringTorqueResp: accessed-variable=RpFromComSafeFD14Rx.FD14_EPS_THA_SteeringTorqueResp
            REC_RpFromComSafeFD14Rx_FD14_THA_SteeringTouchStat: accessed-variable=RpFromComSafeFD14Rx.FD14_THA_SteeringTouchStat
            REC_RpProxiConfigData_ProxiData: accessed-variable=RpProxiConfigData.ProxiData
            REC_RpProxiToSWC_SurroundViewCam_u8: accessed-variable=RpProxiToSWC.SurroundViewCam_u8
            REC_RpProxiToSWC_TyreSz_u16: accessed-variable=RpProxiToSWC.TyreSz_u16
            REC_RpVcanRxQM_ME_VehInp_to_IpcSignals_QM_t: accessed-variable=RpVcanRxQM.ME_VehInp_to_IpcSignals_QM_t
            REC_R_SSM_2_State_State_2_0: accessed-variable=R_SSM_2_State.State_2_0
            REC_R_SSM_2_State_State_2_1: accessed-variable=R_SSM_2_State.State_2_1
            REC_R_SSM_QNXState_State_QNX: accessed-variable=R_SSM_QNXState.State_QNX
            REC_RpMEProxi_ME_Proxi_MPU1_0_to_MCU1_0_t: accessed-variable=RpMEProxi.ME_Proxi_MPU1_0_to_MCU1_0_t
            REC_R_SystemState_SystemState: accessed-variable=R_SystemState.SystemState
            REC_RpTRSC_ME_VehOut_TRSC_t: accessed-variable=RpTRSC.ME_VehOut_TRSC_t
            REC_RpAPSMPAOut_TbAP_APSMPAOut_t: accessed-variable=RpAPSMPAOut.TbAP_APSMPAOut_t
            REC_RpDriveAssistStatOut_TbAP_DriveAssistStatOut_t: accessed-variable=RpDriveAssistStatOut.TbAP_DriveAssistStatOut_t
            REC_RpFeatureOutputsTHA_TbTHASmVc_FeatureOutputs_t: accessed-variable=RpFeatureOutputsTHA.TbTHASmVc_FeatureOutputs_t
            REC_RpProxiToSWC_Fullautomaticparking: accessed-variable=RpProxiToSWC.Fullautomaticparking
            REC_RpProxiToSWC_PAMConfig_u8: accessed-variable=RpProxiToSWC.PAMConfig_u8
            REC_RpProxiToSWC_Parkwithstop_u8: accessed-variable=RpProxiToSWC.Parkwithstop_u8
            REC_RpProxiToSWC_Trailerhitchassist_u8: accessed-variable=RpProxiToSWC.Trailerhitchassist_u8
            REC_RpSafeGuardSvsToVCAN_SvsToVCAN_t: accessed-variable=RpSafeGuardSvsToVCAN.SvsToVCAN_t
            REC_RpSafeGuardPAStateOut_TbAP_PAStateOut_t: accessed-variable=RpSafeGuardPAStateOut.TbAP_PAStateOut_t
            REC_RpCVPAMFDData_IFOD_Outputs_CVPAMFDData_t: accessed-variable=RpCVPAMFDData.IFOD_Outputs_CVPAMFDData_t
            REC_RpDtcB12852AData_v_DtcData_u8: accessed-variable=RpDtcB12852AData.v_DtcData_u8
            REC_RpNmStateInfo_v_IsNmStateNormal_b: accessed-variable=RpNmStateInfo.v_IsNmStateNormal_b
            REC_RpPlantMode_Status: accessed-variable=RpPlantMode.Status
            REC_RpPAM2BTIpcTxStatus_IpcTxDone: accessed-variable=RpPAM2BTIpcTxStatus.IpcTxDone
        data-send-points:
          129 x access:
            SEND_PpToSwcSafeFD02Rx_APARequestSts: accessed-variable=PpToSwcSafeFD02Rx.APARequestSts
            SEND_PpToSwcSafeFD02Rx_Active_Park_Mode: accessed-variable=PpToSwcSafeFD02Rx.Active_Park_Mode
            SEND_PpToSwcSafeFD02Rx_Active_Park_Prox_Chime: accessed-variable=PpToSwcSafeFD02Rx.Active_Park_Prox_Chime
            SEND_PpToSwcSafeFD02Rx_Backup_Cam_Delay: accessed-variable=PpToSwcSafeFD02Rx.Backup_Cam_Delay
            SEND_PpToSwcSafeFD02Rx_Brk_Stat: accessed-variable=PpToSwcSafeFD02Rx.Brk_Stat
            SEND_PpToSwcSafeFD02Rx_CmdIgnSts: accessed-variable=PpToSwcSafeFD02Rx.CmdIgnSts
            SEND_PpToSwcSafeFD02Rx_DriverDoorSts: accessed-variable=PpToSwcSafeFD02Rx.DriverDoorSts
            SEND_PpToSwcSafeFD02Rx_DynamicGrid: accessed-variable=PpToSwcSafeFD02Rx.DynamicGrid
            SEND_PpToSwcSafeFD02Rx_ExternalTemperature: accessed-variable=PpToSwcSafeFD02Rx.ExternalTemperature
            SEND_PpToSwcSafeFD02Rx_FT_PAMRequestSts: accessed-variable=PpToSwcSafeFD02Rx.FT_PAMRequestSts
            SEND_PpToSwcSafeFD02Rx_Fwrd_Cam_Guidelines: accessed-variable=PpToSwcSafeFD02Rx.Fwrd_Cam_Guidelines
            SEND_PpToSwcSafeFD02Rx_GearEngaged: accessed-variable=PpToSwcSafeFD02Rx.GearEngaged
            SEND_PpToSwcSafeFD02Rx_HAS_Status_C2: accessed-variable=PpToSwcSafeFD02Rx.HAS_Status_C2
            SEND_PpToSwcSafeFD02Rx_LHRDoorSts: accessed-variable=PpToSwcSafeFD02Rx.LHRDoorSts
            SEND_PpToSwcSafeFD02Rx_LanguageSelection: accessed-variable=PpToSwcSafeFD02Rx.LanguageSelection
            SEND_PpToSwcSafeFD02Rx_LatAcceleration_BSM: accessed-variable=PpToSwcSafeFD02Rx.LatAcceleration_BSM
            SEND_PpToSwcSafeFD02Rx_LongAcceleration_BSM: accessed-variable=PpToSwcSafeFD02Rx.LongAcceleration_BSM
            SEND_PpToSwcSafeFD02Rx_LwsAngle: accessed-variable=PpToSwcSafeFD02Rx.LwsAngle
            SEND_PpToSwcSafeFD02Rx_LwsAngleType: accessed-variable=PpToSwcSafeFD02Rx.LwsAngleType
            SEND_PpToSwcSafeFD02Rx_LwsSpeed: accessed-variable=PpToSwcSafeFD02Rx.LwsSpeed
            SEND_PpToSwcSafeFD02Rx_MRM_STATUS_C2: accessed-variable=PpToSwcSafeFD02Rx.MRM_STATUS_C2
            SEND_PpToSwcSafeFD02Rx_PAMRequestSts: accessed-variable=PpToSwcSafeFD02Rx.PAMRequestSts
            SEND_PpToSwcSafeFD02Rx_PamChimeVolumeFront: accessed-variable=PpToSwcSafeFD02Rx.PamChimeVolumeFront
            SEND_PpToSwcSafeFD02Rx_PamChimeVolumeRear: accessed-variable=PpToSwcSafeFD02Rx.PamChimeVolumeRear
            SEND_PpToSwcSafeFD02Rx_PsngrDoorSts: accessed-variable=PpToSwcSafeFD02Rx.PsngrDoorSts
            SEND_PpToSwcSafeFD02Rx_RHRDoorSts: accessed-variable=PpToSwcSafeFD02Rx.RHRDoorSts
            SEND_PpToSwcSafeFD02Rx_RHatchSts: accessed-variable=PpToSwcSafeFD02Rx.RHatchSts
            SEND_PpToSwcSafeFD02Rx_Rear_Brk_Asst: accessed-variable=PpToSwcSafeFD02Rx.Rear_Brk_Asst
            SEND_PpToSwcSafeFD02Rx_SVC_Guidelines: accessed-variable=PpToSwcSafeFD02Rx.SVC_Guidelines
            SEND_PpToSwcSafeFD02Rx_ShiftLeverPosition: accessed-variable=PpToSwcSafeFD02Rx.ShiftLeverPosition
            SEND_PpToSwcSafeFD02Rx_TCASERANGESTATUS: accessed-variable=PpToSwcSafeFD02Rx.TCASERANGESTATUS
            SEND_PpToSwcSafeFD02Rx_TGW_CAMERA_DISP_STAT: accessed-variable=PpToSwcSafeFD02Rx.TGW_CAMERA_DISP_STAT
            SEND_PpToSwcSafeFD02Rx_TRANS_ADAS_Inhibit: accessed-variable=PpToSwcSafeFD02Rx.TRANS_ADAS_Inhibit
            SEND_PpToSwcSafeFD02Rx_TargetGear: accessed-variable=PpToSwcSafeFD02Rx.TargetGear
            SEND_PpToSwcSafeFD02Rx_TrailerConnectionSts: accessed-variable=PpToSwcSafeFD02Rx.TrailerConnectionSts
            SEND_PpToSwcSafeFD02Rx_TransmissionSailingSts: accessed-variable=PpToSwcSafeFD02Rx.TransmissionSailingSts
            SEND_PpToSwcSafeFD02Rx_VehicleSpeedVSOSig: accessed-variable=PpToSwcSafeFD02Rx.VehicleSpeedVSOSig
            SEND_PpToSwcSafeFD02Rx_YawRate_BSM: accessed-variable=PpToSwcSafeFD02Rx.YawRate_BSM
            SEND_PpToSwcSafeFD14Rx_FD14_ACC_Systemsts: accessed-variable=PpToSwcSafeFD14Rx.FD14_ACC_Systemsts
            SEND_PpToSwcSafeFD14Rx_FD14_BSM_THA_Brk_Resp: accessed-variable=PpToSwcSafeFD14Rx.FD14_BSM_THA_Brk_Resp
            SEND_PpToSwcSafeFD14Rx_FD14_BrkPdl_Stat: accessed-variable=PpToSwcSafeFD14Rx.FD14_BrkPdl_Stat
            SEND_PpToSwcSafeFD14Rx_FD14_BrkTrq: accessed-variable=PpToSwcSafeFD14Rx.FD14_BrkTrq
            SEND_PpToSwcSafeFD14Rx_FD14_BrkTrq_Driver: accessed-variable=PpToSwcSafeFD14Rx.FD14_BrkTrq_Driver
            SEND_PpToSwcSafeFD14Rx_FD14_Brk_Stat: accessed-variable=PpToSwcSafeFD14Rx.FD14_Brk_Stat
            SEND_PpToSwcSafeFD14Rx_FD14_EPBSts: accessed-variable=PpToSwcSafeFD14Rx.FD14_EPBSts
            SEND_PpToSwcSafeFD14Rx_FD14_EPS_HandsOnRecognition: accessed-variable=PpToSwcSafeFD14Rx.FD14_EPS_HandsOnRecognition
            SEND_PpToSwcSafeFD14Rx_FD14_ESC_TRSC_Brk_Resp: accessed-variable=PpToSwcSafeFD14Rx.FD14_ESC_TRSC_Brk_Resp
            SEND_PpToSwcSafeFD14Rx_FD14_ExternalBrkRequestsDisabled: accessed-variable=PpToSwcSafeFD14Rx.FD14_ExternalBrkRequestsDisabled
            SEND_PpToSwcSafeFD14Rx_FD14_HAS_Status: accessed-variable=PpToSwcSafeFD14Rx.FD14_HAS_Status
            SEND_PpToSwcSafeFD14Rx_FD14_LHFWheelSpeed: accessed-variable=PpToSwcSafeFD14Rx.FD14_LHFWheelSpeed
            SEND_PpToSwcSafeFD14Rx_FD14_LHF_FastPulseCounter: accessed-variable=PpToSwcSafeFD14Rx.FD14_LHF_FastPulseCounter
            SEND_PpToSwcSafeFD14Rx_FD14_LHF_Spin: accessed-variable=PpToSwcSafeFD14Rx.FD14_LHF_Spin
            SEND_PpToSwcSafeFD14Rx_FD14_LHF_WheelSensorFailSts: accessed-variable=PpToSwcSafeFD14Rx.FD14_LHF_WheelSensorFailSts
            SEND_PpToSwcSafeFD14Rx_FD14_LHRWheelSpeed: accessed-variable=PpToSwcSafeFD14Rx.FD14_LHRWheelSpeed
            SEND_PpToSwcSafeFD14Rx_FD14_LHR_FastPulseCounter: accessed-variable=PpToSwcSafeFD14Rx.FD14_LHR_FastPulseCounter
            SEND_PpToSwcSafeFD14Rx_FD14_LHR_Spin: accessed-variable=PpToSwcSafeFD14Rx.FD14_LHR_Spin
            SEND_PpToSwcSafeFD14Rx_FD14_LHR_WheelSensorFailSts: accessed-variable=PpToSwcSafeFD14Rx.FD14_LHR_WheelSensorFailSts
            SEND_PpToSwcSafeFD14Rx_FD14_LatAccelerationFailSts_BSM: accessed-variable=PpToSwcSafeFD14Rx.FD14_LatAccelerationFailSts_BSM
            SEND_PpToSwcSafeFD14Rx_FD14_LatAccelerationOffset_BSM: accessed-variable=PpToSwcSafeFD14Rx.FD14_LatAccelerationOffset_BSM
            SEND_PpToSwcSafeFD14Rx_FD14_LatAcceleration_BSM: accessed-variable=PpToSwcSafeFD14Rx.FD14_LatAcceleration_BSM
            SEND_PpToSwcSafeFD14Rx_FD14_LongAccelerationFailSts_BSM: accessed-variable=PpToSwcSafeFD14Rx.FD14_LongAccelerationFailSts_BSM
            SEND_PpToSwcSafeFD14Rx_FD14_LongAccelerationOffset_BSM: accessed-variable=PpToSwcSafeFD14Rx.FD14_LongAccelerationOffset_BSM
            SEND_PpToSwcSafeFD14Rx_FD14_LongAcceleration_BSM: accessed-variable=PpToSwcSafeFD14Rx.FD14_LongAcceleration_BSM
            SEND_PpToSwcSafeFD14Rx_FD14_LwsAngle: accessed-variable=PpToSwcSafeFD14Rx.FD14_LwsAngle
            SEND_PpToSwcSafeFD14Rx_FD14_LwsAngleType: accessed-variable=PpToSwcSafeFD14Rx.FD14_LwsAngleType
            SEND_PpToSwcSafeFD14Rx_FD14_LwsSpeed: accessed-variable=PpToSwcSafeFD14Rx.FD14_LwsSpeed
            SEND_PpToSwcSafeFD14Rx_FD14_PAM_Brk_Rq_RspSts: accessed-variable=PpToSwcSafeFD14Rx.FD14_PAM_Brk_Rq_RspSts
            SEND_PpToSwcSafeFD14Rx_FD14_ParkingGearShiftReq_BSM: accessed-variable=PpToSwcSafeFD14Rx.FD14_ParkingGearShiftReq_BSM
            SEND_PpToSwcSafeFD14Rx_FD14_ParkingInterventionSts: accessed-variable=PpToSwcSafeFD14Rx.FD14_ParkingInterventionSts
            SEND_PpToSwcSafeFD14Rx_FD14_REF_VEH_SPEED: accessed-variable=PpToSwcSafeFD14Rx.FD14_REF_VEH_SPEED
            SEND_PpToSwcSafeFD14Rx_FD14_RHFWheelSpeed: accessed-variable=PpToSwcSafeFD14Rx.FD14_RHFWheelSpeed
            SEND_PpToSwcSafeFD14Rx_FD14_RHF_FastPulseCounter: accessed-variable=PpToSwcSafeFD14Rx.FD14_RHF_FastPulseCounter
            SEND_PpToSwcSafeFD14Rx_FD14_RHF_Spin: accessed-variable=PpToSwcSafeFD14Rx.FD14_RHF_Spin
            SEND_PpToSwcSafeFD14Rx_FD14_RHF_WheelSensorFailSts: accessed-variable=PpToSwcSafeFD14Rx.FD14_RHF_WheelSensorFailSts
            SEND_PpToSwcSafeFD14Rx_FD14_RHRWheelSpeed: accessed-variable=PpToSwcSafeFD14Rx.FD14_RHRWheelSpeed
            SEND_PpToSwcSafeFD14Rx_FD14_RHR_FastPulseCounter: accessed-variable=PpToSwcSafeFD14Rx.FD14_RHR_FastPulseCounter
            SEND_PpToSwcSafeFD14Rx_FD14_RHR_Spin: accessed-variable=PpToSwcSafeFD14Rx.FD14_RHR_Spin
            SEND_PpToSwcSafeFD14Rx_FD14_RHR_WheelSensorFailSts: accessed-variable=PpToSwcSafeFD14Rx.FD14_RHR_WheelSensorFailSts
            SEND_PpToSwcSafeFD14Rx_FD14_SPM_Lat_Ctrl_ResponseSts: accessed-variable=PpToSwcSafeFD14Rx.FD14_SPM_Lat_Ctrl_ResponseSts
            SEND_PpToSwcSafeFD14Rx_FD14_Slope: accessed-variable=PpToSwcSafeFD14Rx.FD14_Slope
            SEND_PpToSwcSafeFD14Rx_FD14_Steering_Column_Torque: accessed-variable=PpToSwcSafeFD14Rx.FD14_Steering_Column_Torque
            SEND_PpToSwcSafeFD14Rx_FD14_VehicleSpeedVSOSig: accessed-variable=PpToSwcSafeFD14Rx.FD14_VehicleSpeedVSOSig
            SEND_PpToSwcSafeFD14Rx_FD14_VehicleSpeedVSOSig_B2: accessed-variable=PpToSwcSafeFD14Rx.FD14_VehicleSpeedVSOSig_B2
            SEND_PpToSwcSafeFD14Rx_FD14_VehicleStandStillSts: accessed-variable=PpToSwcSafeFD14Rx.FD14_VehicleStandStillSts
            SEND_PpToSwcSafeFD14Rx_FD14_YawRateFailSts_BSM: accessed-variable=PpToSwcSafeFD14Rx.FD14_YawRateFailSts_BSM
            SEND_PpToSwcSafeFD14Rx_FD14_YawRate_BSM: accessed-variable=PpToSwcSafeFD14Rx.FD14_YawRate_BSM
            SEND_PpToSwcSafeFD02Rx_ASCM_Stat: accessed-variable=PpToSwcSafeFD02Rx.ASCM_Stat
            SEND_PpToSwcSafeFD02Rx_ASCM_SysFail: accessed-variable=PpToSwcSafeFD02Rx.ASCM_SysFail
            SEND_PpToSwcSafeFD02Rx_ECM_THA_Resp: accessed-variable=PpToSwcSafeFD02Rx.ECM_THA_Resp
            SEND_PpToSwcSafeFD02Rx_ECM_TRSC_Resp: accessed-variable=PpToSwcSafeFD02Rx.ECM_TRSC_Resp
            SEND_PpToSwcSafeFD02Rx_ESS_ENG_ST_W: accessed-variable=PpToSwcSafeFD02Rx.ESS_ENG_ST_W
            SEND_PpToSwcSafeFD02Rx_EngineSts_W: accessed-variable=PpToSwcSafeFD02Rx.EngineSts_W
            SEND_PpToSwcSafeFD02Rx_FL_Lvl: accessed-variable=PpToSwcSafeFD02Rx.FL_Lvl
            SEND_PpToSwcSafeFD02Rx_FL_Lvl_Adj: accessed-variable=PpToSwcSafeFD02Rx.FL_Lvl_Adj
            SEND_PpToSwcSafeFD02Rx_FR_Lvl: accessed-variable=PpToSwcSafeFD02Rx.FR_Lvl
            SEND_PpToSwcSafeFD02Rx_FR_Lvl_Adj: accessed-variable=PpToSwcSafeFD02Rx.FR_Lvl_Adj
            SEND_PpToSwcSafeFD02Rx_GearEngagedForDisplay: accessed-variable=PpToSwcSafeFD02Rx.GearEngagedForDisplay
            SEND_PpToSwcSafeFD02Rx_HU_TRSC_EnableBtn_Sts: accessed-variable=PpToSwcSafeFD02Rx.HU_TRSC_EnableBtn_Sts
            SEND_PpToSwcSafeFD02Rx_RL_Lvl: accessed-variable=PpToSwcSafeFD02Rx.RL_Lvl
            SEND_PpToSwcSafeFD02Rx_RL_Lvl_Adj: accessed-variable=PpToSwcSafeFD02Rx.RL_Lvl_Adj
            SEND_PpToSwcSafeFD02Rx_RR_Lvl: accessed-variable=PpToSwcSafeFD02Rx.RR_Lvl
            SEND_PpToSwcSafeFD02Rx_RR_Lvl_Adj: accessed-variable=PpToSwcSafeFD02Rx.RR_Lvl_Adj
            SEND_PpToSwcSafeFD02Rx_VIN_DATA: accessed-variable=PpToSwcSafeFD02Rx.VIN_DATA
            SEND_PpToSwcSafeFD02Rx_VIN_MSG: accessed-variable=PpToSwcSafeFD02Rx.VIN_MSG
            SEND_PpToSwcSafeFD14Rx_FD14_ECM_THA_Resp: accessed-variable=PpToSwcSafeFD14Rx.FD14_ECM_THA_Resp
            SEND_PpToSwcSafeFD14Rx_FD14_ECM_TRSC_Resp: accessed-variable=PpToSwcSafeFD14Rx.FD14_ECM_TRSC_Resp
            SEND_PpToSwcSafeFD14Rx_FD14_ESS_ENG_ST_W: accessed-variable=PpToSwcSafeFD14Rx.FD14_ESS_ENG_ST_W
            SEND_PpToSwcSafeFD14Rx_FD14_EngineSts_W: accessed-variable=PpToSwcSafeFD14Rx.FD14_EngineSts_W
            SEND_PpToSwcSafeFD02Rx_PdlPosActual: accessed-variable=PpToSwcSafeFD02Rx.PdlPosActual
            SEND_PpToSwcSafeFD14Rx_FD14_PdlPosActual: accessed-variable=PpToSwcSafeFD14Rx.FD14_PdlPosActual
            SEND_PpToSwcSafeFD02Rx_CM_TCH_STAT: accessed-variable=PpToSwcSafeFD02Rx.CM_TCH_STAT
            SEND_PpToSwcSafeFD02Rx_CM_TCH_X_COORD: accessed-variable=PpToSwcSafeFD02Rx.CM_TCH_X_COORD
            SEND_PpToSwcSafeFD02Rx_CM_TCH_Y_COORD: accessed-variable=PpToSwcSafeFD02Rx.CM_TCH_Y_COORD
            SEND_PpToSwcSafeFD02Rx_CameraDisplaySts2: accessed-variable=PpToSwcSafeFD02Rx.CameraDisplaySts2
            SEND_PpToSwcSafeFD02Rx_EPS_SteeringTouchStat: accessed-variable=PpToSwcSafeFD02Rx.EPS_SteeringTouchStat
            SEND_PpToSwcSafeFD02Rx_EPS_SteeringTouq_Resp: accessed-variable=PpToSwcSafeFD02Rx.EPS_SteeringTouq_Resp
            SEND_PpToSwcSafeFD02Rx_EPS_THA_DriverTorqueOverride: accessed-variable=PpToSwcSafeFD02Rx.EPS_THA_DriverTorqueOverride
            SEND_PpToSwcSafeFD02Rx_EPS_THA_SteeringTorqueResp: accessed-variable=PpToSwcSafeFD02Rx.EPS_THA_SteeringTorqueResp
            SEND_PpToSwcSafeFD02Rx_ITBM_TrlrStat: accessed-variable=PpToSwcSafeFD02Rx.ITBM_TrlrStat
            SEND_PpToSwcSafeFD02Rx_ShiftLeverPositionReq: accessed-variable=PpToSwcSafeFD02Rx.ShiftLeverPositionReq
            SEND_PpToSwcSafeFD02Rx_Shifter_ADAS_Inhibit: accessed-variable=PpToSwcSafeFD02Rx.Shifter_ADAS_Inhibit
            SEND_PpToSwcSafeFD02Rx_THA_SteeringTouchStat: accessed-variable=PpToSwcSafeFD02Rx.THA_SteeringTouchStat
            SEND_PpToSwcSafeFD14Rx_FD14_EPS_SteeringTouchStat: accessed-variable=PpToSwcSafeFD14Rx.FD14_EPS_SteeringTouchStat
            SEND_PpToSwcSafeFD14Rx_FD14_EPS_SteeringTouq_Resp: accessed-variable=PpToSwcSafeFD14Rx.FD14_EPS_SteeringTouq_Resp
            SEND_PpToSwcSafeFD14Rx_FD14_EPS_THA_DriverTorqueOverride: accessed-variable=PpToSwcSafeFD14Rx.FD14_EPS_THA_DriverTorqueOverride
            SEND_PpToSwcSafeFD14Rx_FD14_EPS_THA_SteeringTorqueResp: accessed-variable=PpToSwcSafeFD14Rx.FD14_EPS_THA_SteeringTorqueResp
            SEND_PpToSwcSafeFD14Rx_FD14_THA_SteeringTouchStat: accessed-variable=PpToSwcSafeFD14Rx.FD14_THA_SteeringTouchStat
            SEND_PpVIN_MessageFault_VIN_InvalidValueFlag: accessed-variable=PpVIN_MessageFault.VIN_InvalidValueFlag
            SEND_PpVIN_MessageFault_VIN_MissingMessageFlag: accessed-variable=PpVIN_MessageFault.VIN_MissingMessageFlag
        mode switch point SWITCH_PpMode_VehicleSpeedCheck_Mode: mode-group=PpMode_VehicleSpeedCheck.Mode
        sync call SC_RpIpcTxData_IPC_Write_v: operation=RpIpcTxData.IPC_Write_v
        sync call SC_RpError_CS_B_ReportErrorStatus1_0_B: operation=RpError_CS_B.ReportErrorStatus1_0_B
        sync call SC_RpE2EServices_ME_E2E_Check: operation=RpE2EServices.ME_E2E_Check
  swc implementation SWC_SafeVCANRx_Implementation: behavior=SWC_SafeVCANRx_InternalBehavior
